# MKM14ZA5 register map
Vendor: Freescale Semiconductor, Inc.; Series: Kinetis_M; File version: 1.6
CPU: CM0PLUS r0p0, little endian, no MPU, no FPU, VTOR, 2 interrupt priority bits
Registers are 8-bit, read-write, reset 0x0 unless marked. A register's access mark holds for its fields unless they carry their own. Offsets are from the block's base; [hi:lo] are bit positions; 'fields as' and 'values as' point back to an identical list.

## RTC — Real Time Clock
Base 0x40050000; register names take the prefix RTC_
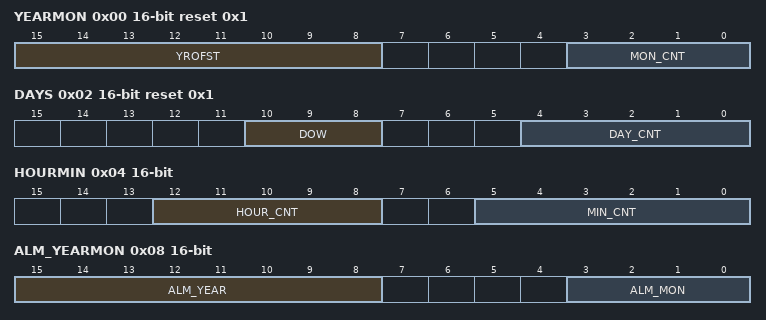
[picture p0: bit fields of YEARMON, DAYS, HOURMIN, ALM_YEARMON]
0x00 YEARMON 16-bit reset 0x1 — RTC Year and Month Counters Register
  [15:8] YROFST — Year Offset Count Value
  [3:0] MON_CNT — These bits give the value of the Months Counter . Valid Values are:
    0=Illegal Value; 1=January; 2=October; 3=November
0x02 DAYS 16-bit reset 0x1 — RTC Days and Day-of-Week Counters Register
  [10:8] DOW — Day of Week Counter Value.
    0=Sunday; 1=Monday
  [4:0] DAY_CNT — Days Counter Value.
0x04 HOURMIN 16-bit — RTC Hours and Minutes Counters Register
  [12:8] HOUR_CNT — Hours Counter Value.
  [5:0] MIN_CNT — Minutes Counter Value.
0x06 SECONDS 16-bit — RTC Seconds Counters Register
  [5:0] SEC_CNT — Seconds Counter Value.
0x08 ALM_YEARMON 16-bit — RTC Year and Months Alarm Register
  [15:8] ALM_YEAR — Year Value for Alarm.
  [3:0] ALM_MON — Months Value for Alarm.
0x0A ALM_DAYS 16-bit — RTC Days Alarm Register
  [4:0] ALM_DAY — Days Value for Alarm.
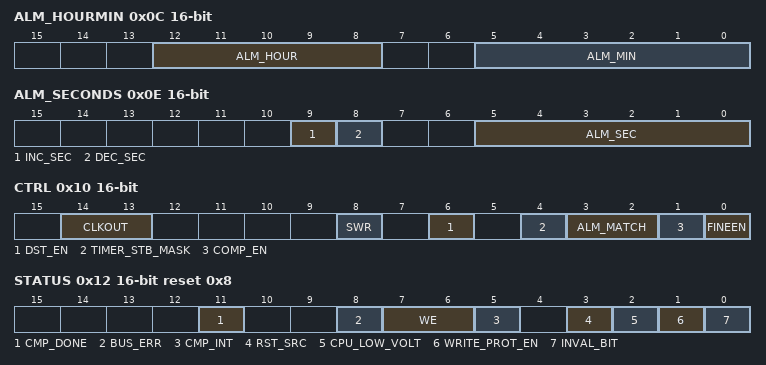
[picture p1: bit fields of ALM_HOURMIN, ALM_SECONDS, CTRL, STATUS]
0x0C ALM_HOURMIN 16-bit — RTC Hours and Minutes Alarm Register
  [12:8] ALM_HOUR — Hours Value for Alarm.
  [5:0] ALM_MIN — Minutes Value for Alarm.
0x0E ALM_SECONDS 16-bit — RTC Seconds Alarm Register
  [9] INC_SEC wo — Increment Seconds Counter by 1.
  [8] DEC_SEC wo — Decrement Seconds Counter by 1.
  [5:0] ALM_SEC — Seconds Value for Alarm. Same as Seconds Counter Value in SECONDSRTC Seconds Counters Register .
0x10 CTRL 16-bit — RTC Control Register
  [14:13] CLKOUT — RTC Clock Output Selection.
    0=No Output Clock; 1=Fine 1 Hz Clock; 2=32.768 kHz Clock; 3=Coarse 1 Hz Clock
  [8] SWR wo — Software Reset bit.
    0=Software Reset cleared; 1=Software Reset asserted
  [6] DST_EN — Daylight Saving Enable.
    0=Disabled. Daylight saving changes are not applied. Daylight saving registers can be modified.; 1=Enabled. Daylight saving changes are applied.
  [4] TIMER_STB_MASK — Sampling timer clocks mask
    1=Sampling clocks are gated in standby mode; 0=Sampling clocks are not gated when in standby mode
  [3:2] ALM_MATCH — Alarm Match bits.
    0=Only Seconds, Minutes, and Hours matched; 1=Only Seconds, Minutes, Hours, and Days matched; 2=Only Seconds, Minutes, Hours, Days, and Months matched
  [1] COMP_EN — Compensation enable bit 1'b0:- Coarse Compensation is disabled
  [0] FINEEN — Fine compensation enable bit
    1=Fine compensation is enabled; 0=Fine compensation is disabled
0x12 STATUS 16-bit reset 0x8 — RTC Status Register
  [11] CMP_DONE — Compensation Done bit.
    0=Compensation busy or not enabled; 1=Compensation completed
  [8] BUS_ERR — Bus Error bit.
    0=Read and Write accesses are normal; 1=Read or Write accesses occurred when INVAL_BIT was asserted
  [7:6] WE wo — Write Enable bits.
    2=Enable Write Protection - Registers are locked
  [5] CMP_INT ro — Compensation Interval bit.
  [3] RST_SRC ro — Reset Source bit.
    0=Part was reset due to Standby Mode Exit (that is when VDD is powered up and VBAT was not powered down at all); 1=Part was reset due to Power-On Reset (that is Power On Reset when both VBAT and VDD are powered up)
  [2] CPU_LOW_VOLT ro — CPU Low Voltage Warning status bit.
    0=CPU in Normal Operating Voltage; 1=CPU Voltage is below Normal Operating Voltage. RTC Registers in read-only mode.
  [1] WRITE_PROT_EN ro — Write Protect Enable status bit.
    0=Registers are unlocked and can be accessed; 1=Registers are locked and in read-only mode
  [0] INVAL_BIT ro — Invalidate CPU read/write access bit.
    0=Time /Date Counters can be read/written. Time /Date is valid.; 1=Time /Date Counter values are changing or Time /Date is invalid and cannot be read or written
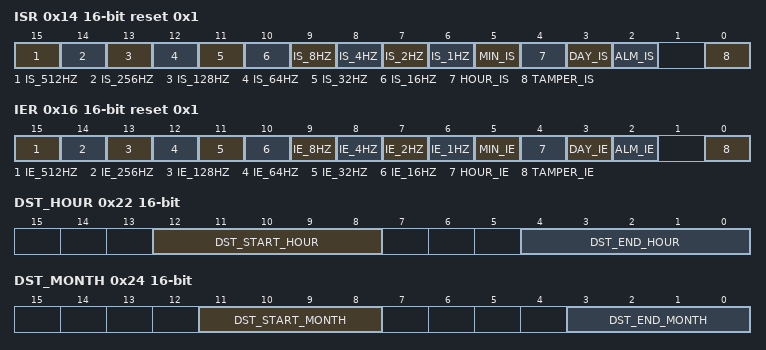
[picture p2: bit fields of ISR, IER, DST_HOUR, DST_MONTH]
0x14 ISR 16-bit reset 0x1 — RTC Interrupt Status Register
  [15] IS_512HZ — 512 Hz Interval Interrupt Status bit.
    0=Interrupt is de-asserted; 1=Interrupt is asserted
  [14] IS_256HZ — 256 Hz Interval Interrupt Status bit.
    0=Interrupt is de-asserted; 1=Interrupt is asserted
  [13] IS_128HZ — 128 Hz Interval Interrupt Status bit.
    0=Interrupt is de-asserted; 1=Interrupt is asserted
  [12] IS_64HZ — 64 Hz Interval Interrupt Status bit.
    0=Interrupt is de-asserted; 1=Interrupt is asserted
  [11] IS_32HZ — 32 Hz Interval Interrupt Status bit.
    0=Interrupt is de-asserted; 1=Interrupt is asserted
  [10] IS_16HZ — 16 Hz Interval Interrupt Status bit.
    0=Interrupt is de-asserted; 1=Interrupt is asserted
  [9] IS_8HZ — 8 Hz Interval Interrupt Status bit.
    0=Interrupt is de-asserted; 1=Interrupt is asserted
  [8] IS_4HZ — 4 Hz Interval Interrupt Status bit.
    0=Interrupt is de-asserted; 1=Interrupt is asserted
  [7] IS_2HZ — 2 Hz Interval Interrupt Status bit.
    0=Interrupt is de-asserted; 1=Interrupt is asserted
  [6] IS_1HZ — 1 Hz Interval Interrupt Status bit.
    0=Interrupt is de-asserted; 1=Interrupt is asserted
  [5] MIN_IS — Minutes Interrupt Status bit.
    0=Interrupt is de-asserted; 1=Interrupt is asserted
  [4] HOUR_IS — Hours Interrupt Status bit.
    0=Interrupt is de-asserted; 1=Interrupt is asserted
  [3] DAY_IS — Days Interrupt Status bit.
    0=Interrupt is de-asserted; 1=Interrupt is asserted
  [2] ALM_IS — Alarm Interrupt Status bit.
    0=Interrupt is de-asserted; 1=Interrupt is asserted
  [0] TAMPER_IS ro — Tamper Interrupt Status bit.
    0=Interrupt is de-asserted; 1=Interrupt is asserted (Default on reset) 
0x16 IER 16-bit reset 0x1 — RTC Interrupt Enable Register
  [15] IE_512HZ — 512 Hz Interval Interrupt Enable bit.
    0=Interrupt is disabled; 1=Interrupt is enabled
  [14] IE_256HZ — 256 Hz Interval Interrupt Enable bit.
    0=Interrupt is disabled; 1=Interrupt is enabled
  [13] IE_128HZ — 128 Hz Interval Interrupt Enable bit.
    0=Interrupt is disabled; 1=Interrupt is enabled
  [12] IE_64HZ — 64 Hz Interval Interrupt Enable bit.
    0=Interrupt is disabled; 1=Interrupt is enabled
  [11] IE_32HZ — 32 Hz Interval Interrupt Enable bit.
    0=Interrupt is disabled; 1=Interrupt is enabled
  [10] IE_16HZ — 16 Hz Interval Interrupt Enable bit.
    0=Interrupt is disabled; 1=Interrupt is enabled
  [9] IE_8HZ — 8 Hz Interval Interrupt Enable bit.
    0=Interrupt is disabled; 1=Interrupt is enabled
  [8] IE_4HZ — 4 Hz Interval Interrupt Enable bit.
    0=Interrupt is disabled; 1=Interrupt is enabled
  [7] IE_2HZ — 2 Hz Interval Interrupt Enable bit.
    0=Interrupt is disabled; 1=Interrupt is enabled
  [6] IE_1HZ — 1 Hz Interval Interrupt Enable bit.
    0=Interrupt is disabled; 1=Interrupt is enabled
  [5] MIN_IE — Minutes Interrupt Enable bit.
    0=Interrupt is disabled; 1=Interrupt is enabled
  [4] HOUR_IE — Hours Interrupt Enable bit.
    0=Interrupt is disabled; 1=Interrupt is enabled
  [3] DAY_IE — Days Interrupt Enable bit.
    0=Interrupt is disabled; 1=Interrupt is enabled
  [2] ALM_IE — Alarm Interrupt Enable bit.
    0=Interrupt is disabled; 1=Interrupt is enabled
  [0] TAMPER_IE — Tamper Interrupt Enable bit.
    0=Interrupt is disabled; 1=Interrupt is enabled (Default on reset)
0x20 GP_DATA_REG 16-bit — RTC General Purpose Data Register
  [15:0] GP_DATA_REG — General Purpose Data bits for use by MCU. These bits are directly output from MCU.
0x22 DST_HOUR 16-bit — RTC Daylight Saving Hour Register
  [12:8] DST_START_HOUR — Daylight Saving Time (DST) Hours Start Value.
  [4:0] DST_END_HOUR — Daylight Saving Time (DST) Hours End Value.
0x24 DST_MONTH 16-bit — RTC Daylight Saving Month Register
  [11:8] DST_START_MONTH — Daylight Saving Time (DST) Month Start Value.
  [3:0] DST_END_MONTH — Daylight Saving Time (DST) Month End Value.
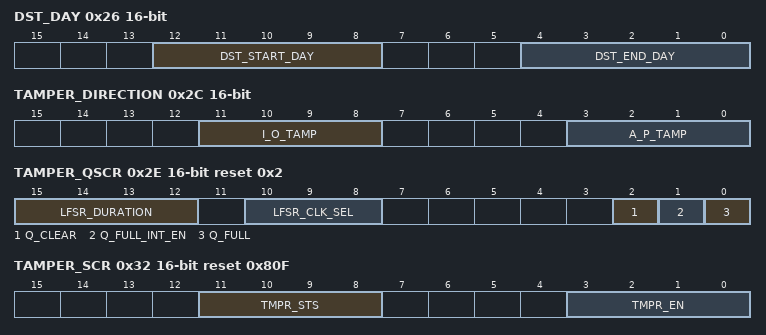
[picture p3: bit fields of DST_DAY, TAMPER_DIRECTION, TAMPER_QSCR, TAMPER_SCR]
0x26 DST_DAY 16-bit — RTC Daylight Saving Day Register
  [12:8] DST_START_DAY — Daylight Saving Time (DST) Day Start Value.
  [4:0] DST_END_DAY — Daylight Saving Time (DST) Day End Value.
0x28 COMPEN 16-bit — RTC Compensation Register
  [15:0] COMPEN_VAL — Compensation Value
0x2C TAMPER_DIRECTION 16-bit
  [11:8] I_O_TAMP — Defines the I/O capability of tamper pins
  [3:0] A_P_TAMP — Defines the active/passive selection of the tamper pins.
0x2E TAMPER_QSCR 16-bit reset 0x2 — Tamper Queue Status and Control Register
  [15:12] LFSR_DURATION — LFSR Filter duration period:- Denotes the LFSR clocks after which the LFSR shifts its value
  [10:8] LFSR_CLK_SEL — This field defines the clock selection for LFSR module
  [2] Q_CLEAR wo — This field when set clears the Tamper Queue
  [1] Q_FULL_INT_EN — Queue full interrupt enable bit.
  [0] Q_FULL — Tamper Queue full status bit.
0x32 TAMPER_SCR 16-bit reset 0x80F — RTC Tamper Status and Control Register
  [11:8] TMPR_STS — Tamper Status Bit
  [3:0] TMPR_EN — Tamper Control
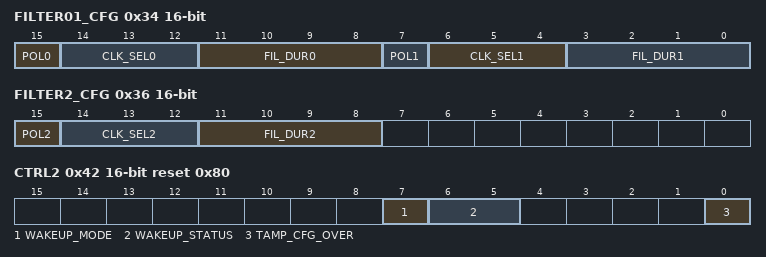
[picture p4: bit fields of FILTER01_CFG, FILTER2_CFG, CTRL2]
0x34 FILTER01_CFG 16-bit — RTC Tamper 0 1 Filter Configuration Register
  [15] POL0 — Tamper Detect Input Bit 0 Polarity Control
    0=Tamper detect input bit 0 is active high; 1=Tamper detect input bit 0 is active low
  [14:12] CLK_SEL0 — Tamper Filter 0 Clock Select
    0=32 kHz clock; 1=512 Hz clock; 2=128 Hz clock; 3=64 Hz clock; 4=16 Hz clock; 5=8 Hz clock; 6=4 Hz clock; 7=2 Hz clock
  [11:8] FIL_DUR0 — Tamper Detect Bit 0 Filter Duration
    0=Filtering operation disabled
  [7] POL1 — Tamper Detect Input Bit 1 Polarity Control
    0=Tamper detect input bit 1 is active high; 1=Tamper detect input bit 1 is active low
  [6:4] CLK_SEL1 — Tamper Filter 1 Clock Select
    values as CLK_SEL0
  [3:0] FIL_DUR1 — Tamper Detect Bit 1 Filter Duration
    0=Filtering operation disabled
0x36 FILTER2_CFG 16-bit — RTC Tamper 2 Filter Configuration Register
  [15] POL2 — Tamper Detect Input Bit 2 Polarity Control
    0=Tamper detect input bit 2 is active high; 1=Tamper detect input bit 2 is active low
  [14:12] CLK_SEL2 — Tamper Filter 2 Clock Select
    values as FILTER01_CFG.CLK_SEL0
  [11:8] FIL_DUR2 — Tamper Detect Bit 2 Filter Duration
    0=Filtering operation disabled
0x40 TAMPER_QUEUE 16-bit ro
  [15:0] TAMPER_DATA — Tamper type stamp and pin number information register
0x42 CTRL2 16-bit reset 0x80 — RTC Control 2 Register
  [7] WAKEUP_MODE
    0=Tamper pin 0 is used as the tamper pin; 1=Tamper pin 0 is used as a wakeup/hibernation pin
  [6:5] WAKEUP_STATUS
    0=The wakeup/hibernation pin is in HiZ mode; 1=The wakeup/hibernation pin is at logic 0. MCU is in sleep mode.; 2=The wakeup/ hibernation pin is at logic 1. MCU is in sleep mode.
  [0] TAMP_CFG_OVER — Tamper Configuration Over
    0=Tamper filter processing disabled; 1=Tamper filter processing enabled

## Notices in the file
Redistribution and use in source and binary forms, with or without modification,
are permitted provided that the following conditions are met:
o Redistributions of source code must retain the above copyright notice, this list
of conditions and the following disclaimer.
o Redistributions in binary form must reproduce the above copyright notice, this
list of conditions and the following disclaimer in the documentation and/or
other materials provided with the distribution.
o Neither the name of Freescale Semiconductor, Inc. nor the names of its
contributors may be used to endorse or promote products derived from this
software without specific prior written permission.
THIS SOFTWARE IS PROVIDED BY THE COPYRIGHT HOLDERS AND CONTRIBUTORS "AS IS" AND
ANY EXPRESS OR IMPLIED WARRANTIES, INCLUDING, BUT NOT LIMITED TO, THE IMPLIED
WARRANTIES OF MERCHANTABILITY AND FITNESS FOR A PARTICULAR PURPOSE ARE
DISCLAIMED. IN NO EVENT SHALL THE COPYRIGHT HOLDER OR CONTRIBUTORS BE LIABLE FOR
ANY DIRECT, INDIRECT, INCIDENTAL, SPECIAL, EXEMPLARY, OR CONSEQUENTIAL DAMAGES
(INCLUDING, BUT NOT LIMITED TO, PROCUREMENT OF SUBSTITUTE GOODS OR SERVICES;
LOSS OF USE, DATA, OR PROFITS; OR BUSINESS INTERRUPTION) HOWEVER CAUSED AND ON
ANY THEORY OF LIABILITY, WHETHER IN CONTRACT, STRICT LIABILITY, OR TORT
(INCLUDING NEGLIGENCE OR OTHERWISE) ARISING IN ANY WAY OUT OF THE USE OF THIS
SOFTWARE, EVEN IF ADVISED OF THE POSSIBILITY OF SUCH DAMAGE.
